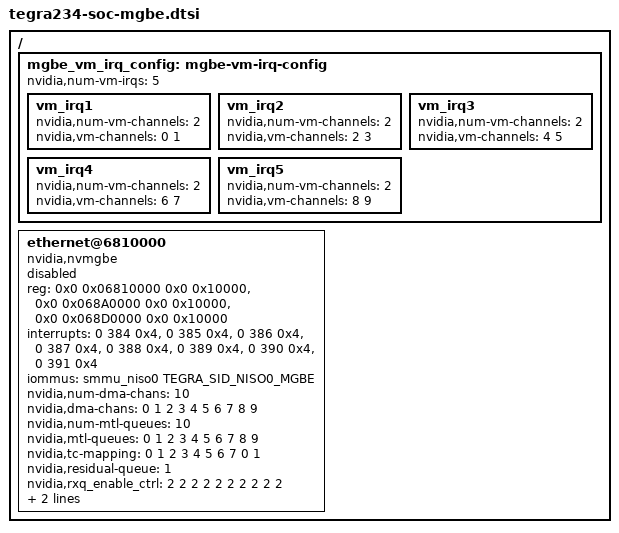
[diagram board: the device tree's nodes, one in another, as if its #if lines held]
/*
 * Copyright (c) 2020-2021, NVIDIA CORPORATION.  All rights reserved.
 *
 * This program is free software; you can redistribute it and/or modify it
 * under the terms and conditions of the GNU General Public License,
 * version 2, as published by the Free Software Foundation.
 *
 * This program is distributed in the hope it will be useful, but WITHOUT
 * ANY WARRANTY; without even the implied warranty of MERCHANTABILITY or
 * FITNESS FOR A PARTICULAR PURPOSE.  See the GNU General Public License for
 * more details.
 *
 * You should have received a copy of the GNU General Public License
 * along with this program.  If not, see <http://www.gnu.org/licenses/>.
 */

/*
 * tegra234-soc-mgbe.dtsi: Ethernet MGBE DTSI file.
 */

/ {
	mgbe_vm_irq_config: mgbe-vm-irq-config {
		nvidia,num-vm-irqs = <5>;
		vm_irq1 {
			nvidia,num-vm-channels = <2>;
			nvidia,vm-channels = <0 1>;
		};
		vm_irq2 {
			nvidia,num-vm-channels = <2>;
			nvidia,vm-channels = <2 3>;
		};
		vm_irq3 {
			nvidia,num-vm-channels = <2>;
			nvidia,vm-channels = <4 5>;
		};
		vm_irq4 {
			nvidia,num-vm-channels = <2>;
			nvidia,vm-channels = <6 7>;
		};
		vm_irq5 {
			nvidia,num-vm-channels = <2>;
			nvidia,vm-channels = <8 9>;
		};
	};

	ethernet@6810000 {
		compatible = "nvidia,nvmgbe";
		reg = <0x0 0x06810000 0x0 0x10000>, /* MGBE base */
		      <0x0 0x068A0000 0x0 0x10000>, /* XPCS base */
		      <0x0 0x068D0000 0x0 0x10000>; /* MACsec RM base */
		reg-names = "mac-base", "xpcs-base", "macsec-base";
		interrupts = 	<0 384 0x4>,	/* common */
				<0 385 0x4>,	/* vm0 */
				<0 386 0x4>,	/* vm1 */
				<0 387 0x4>,	/* vm2 */
				<0 388 0x4>,	/* vm3 */
				<0 389 0x4>,	/* vm4 */
				<0 390 0x4>,	/* MACsec non-secure intr */
				<0 391 0x4>;	/* MACsec secure intr */
		interrupt-names = "common", "vm0", "vm1", "vm2", "vm3", "vm4",
				  "macsec-ns-irq", "macsec-s-irq";
#if TEGRA_IOMMU_DT_VERSION >= DT_VERSION_2
		iommus = <&smmu_niso0 TEGRA_SID_NISO0_MGBE>;
#else
		iommus = <&smmu TEGRA_SID_MGBE>;
#endif
		nvidia,num-dma-chans = <10>;
		nvidia,dma-chans = <0 1 2 3 4 5 6 7 8 9>;
		nvidia,num-mtl-queues = <10>;
		nvidia,mtl-queues = <0 1 2 3 4 5 6 7 8 9>;
		nvidia,tc-mapping = <0 1 2 3 4 5 6 7 0 1>;
		/* Residual Queue can be any valid queue except RxQ0 */
		nvidia,residual-queue = <1>;
		nvidia,rxq_enable_ctrl = <2 2 2 2 2 2 2 2 2 2>;
		nvidia,vm-irq-config = <&mgbe_vm_irq_config>;
		nvidia,tx-queue-prio = <0 1 2 3 4 5 6 7 0 0>;
		status = "disabled";
	};
};
